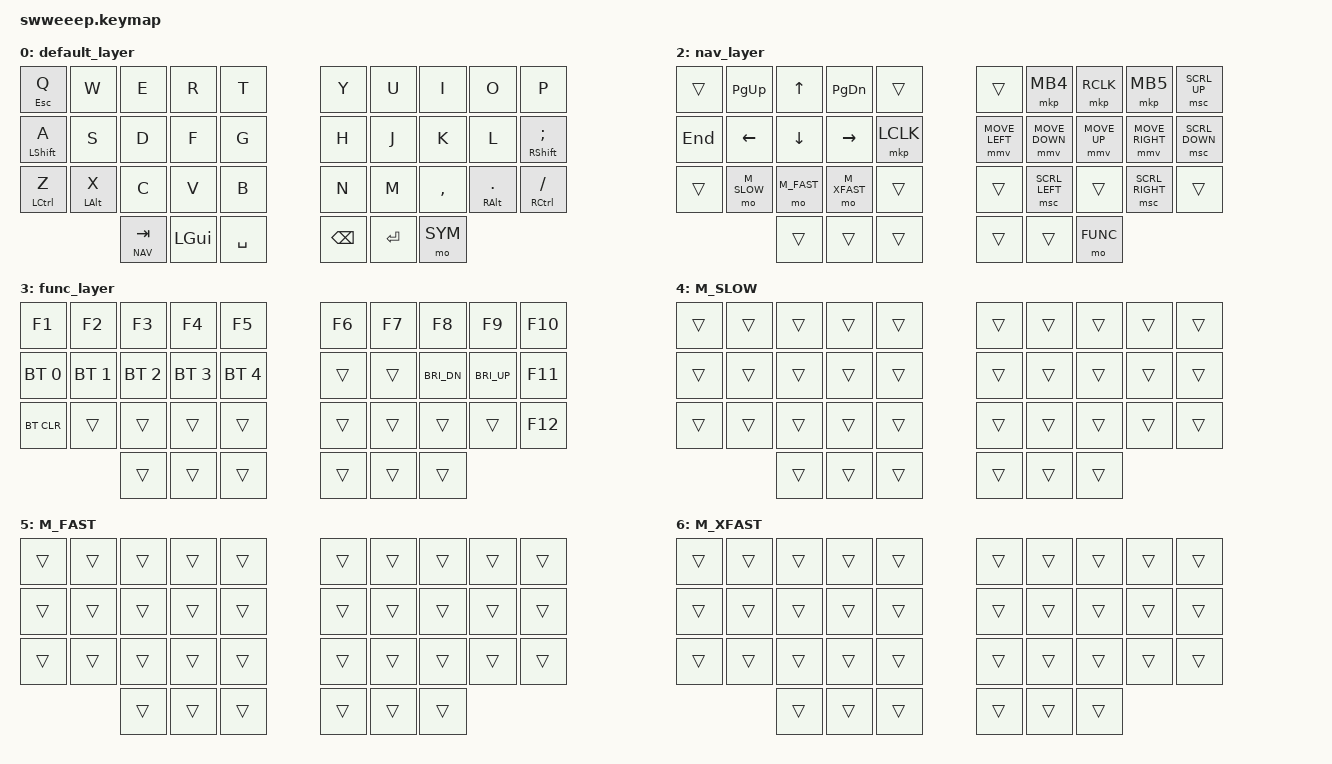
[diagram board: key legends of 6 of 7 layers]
#include <behaviors.dtsi>
#include <dt-bindings/zmk/keys.h>
#include <dt-bindings/zmk/bt.h>
#include <dt-bindings/zmk/pointing.h>
#include <input/processors.dtsi>

// Layer Defines
#define DEFAULT 0
#define SYM     1
#define NAV     2
#define FUNC    3
#define M_SLOW  4
#define M_FAST  5
#define M_XFAST 6


&msc {
    time-to-max-speed-ms = <180>;
    acceleration-exponent = <2>;
};

&mmv_input_listener {
    set_mouse_xfast { 
        layers = <M_XFAST>;
        input-processors = <&zip_xy_scaler 4 1>;
    };
};

&mmv_input_listener {
    set_mouse_fast { 
        layers = <M_FAST>;
        input-processors = <&zip_xy_scaler 2 1>;
    };
};

&mmv_input_listener {
    set_mouse_slow { 
        layers = <M_SLOW>;
        input-processors = <&zip_xy_scaler 1 2>;
    };
};

/ {
    // Custom behaviors to fine-tune hold-tap settings for specific use cases.
    // `hm` uses 'tap-preferred' for home row mods, and `lt_nav_tab` is isolated for independent thumb key tuning.
    behaviors {
        // Hold-Tap for Home Row Mods (Ctrl, Alt, Shift)
        hm: homerow_mods {
            compatible = "zmk,behavior-hold-tap";
            label = "HOMEROW_MODS";
            #binding-cells = <2>;
            tapping-term-ms = <200>;
            quick-tap-ms = <175>;
            flavor = "tap-preferred";
            bindings = <&kp>, <&kp>;
        };

        // Layer-Tap for Thumb Keys
        lt_nav_tab: layer_tap_nav_tab {
            compatible = "zmk,behavior-hold-tap";
            label = "LAYER_TAP_NAV_TAB";
            #binding-cells = <2>;
            tapping-term-ms = <200>;
            flavor = "hold-preferred";
            bindings = <&mo>, <&kp>;
        };

    };

    combos {
        compatible = "zmk,combos";

        // Bootloader: q,w,e, 1 left thumb key and all right thumb keys 
        combo_bootloader {
            timeout-ms = <50>;
            key-positions = <0 1 2 32 33 34 35>;
            bindings = <&bootloader>;
        };

        // Reset: same as above but without w and e
        combo_reset {
            timeout-ms = <50>;
            key-positions = <0 32 33 34 35>;
            bindings = <&sys_reset>;
        };

        // Tab: `e` and `r`
        combo_tab {
            timeout-ms = <50>;
            key-positions = <2 3>;
            bindings = <&kp TAB>;
        };
    };

    keymap {
        compatible = "zmk,keymap";
        default_layer {
            bindings = <
&hm ESC Q   &kp W         &kp E       &kp R         &kp T         &kp Y       &kp U         &kp I         &kp O        &kp P
&hm LSHFT A &kp S         &kp D       &kp F         &kp G         &kp H       &kp J         &kp K         &kp L        &hm RSHFT SEMI
&hm LCTL Z  &hm LALT X    &kp C       &kp V         &kp B         &kp N       &kp M         &kp COMMA     &hm RALT DOT &hm RCTL SLASH
                                    &lt_nav_tab NAV TAB &kp LGUI  &kp SPACE   &kp BSPC      &kp RET       &mo SYM
            >;
        };

        sym_layer {
            bindings = <
&kp N1     &kp N2     &kp N3        &kp N4        &kp N5        &kp N6        &kp N7        &kp N8        &kp N9        &kp N0
&kp LSHFT  &trans     &trans        &trans        &trans        &trans        &trans        &kp LBKT      &kp RBKT      &kp BSLH 
&kp GRAVE  &trans     &trans        &trans        &trans        &trans        &kp LALT      &kp MINUS     &kp EQUAL     &kp SQT
                                    &trans        &trans        &trans        &trans        &trans        &trans        &trans
            >;
        };

        nav_layer {
            bindings = <
&trans     &kp PG_UP  &kp UP        &kp PG_DN     &trans        &trans         &mkp MB4       &mkp RCLK    &mkp MB5        &msc SCRL_UP
&kp END    &kp LEFT   &kp DOWN      &kp RIGHT     &mkp LCLK     &mmv MOVE_LEFT &mmv MOVE_DOWN &mmv MOVE_UP &mmv MOVE_RIGHT &msc SCRL_DOWN
&trans     &mo M_SLOW &mo M_FAST    &mo M_XFAST   &trans        &trans         &msc SCRL_LEFT &trans       &msc SCRL_RIGHT &trans
                                    &trans        &trans        &trans         &trans         &trans       &mo FUNC
            >;
        };

        func_layer {
            bindings = <
&kp F1       &kp F2       &kp F3       &kp F4       &kp F5       &kp F6     &kp F7        &kp F8        &kp F9       &kp F10
&bt BT_SEL 0 &bt BT_SEL 1 &bt BT_SEL 2 &bt BT_SEL 3 &bt BT_SEL 4 &trans     &trans        &kp C_BRI_DN  &kp C_BRI_UP &kp F11
&bt BT_CLR   &trans       &trans       &trans       &trans       &trans     &trans        &trans        &trans       &kp F12
                                    &trans        &trans        &trans     &trans        &trans        &trans
            >;
        };

        M_SLOW {
            bindings = <
&trans  &trans  &trans  &trans  &trans  &trans  &trans  &trans  &trans  &trans
&trans  &trans  &trans  &trans  &trans  &trans  &trans  &trans  &trans  &trans
&trans  &trans  &trans  &trans  &trans  &trans  &trans  &trans  &trans  &trans
                        &trans  &trans  &trans  &trans  &trans  &trans
            >;
        };

        M_FAST {
            bindings = <
&trans  &trans  &trans  &trans  &trans  &trans  &trans  &trans  &trans  &trans
&trans  &trans  &trans  &trans  &trans  &trans  &trans  &trans  &trans  &trans
&trans  &trans  &trans  &trans  &trans  &trans  &trans  &trans  &trans  &trans
                        &trans  &trans  &trans  &trans  &trans  &trans
            >;
        };

        M_XFAST {
            bindings = <
&trans  &trans  &trans  &trans  &trans  &trans  &trans  &trans  &trans  &trans
&trans  &trans  &trans  &trans  &trans  &trans  &trans  &trans  &trans  &trans
&trans  &trans  &trans  &trans  &trans  &trans  &trans  &trans  &trans  &trans
                        &trans  &trans  &trans  &trans  &trans  &trans
            >;
        };
    };
};
